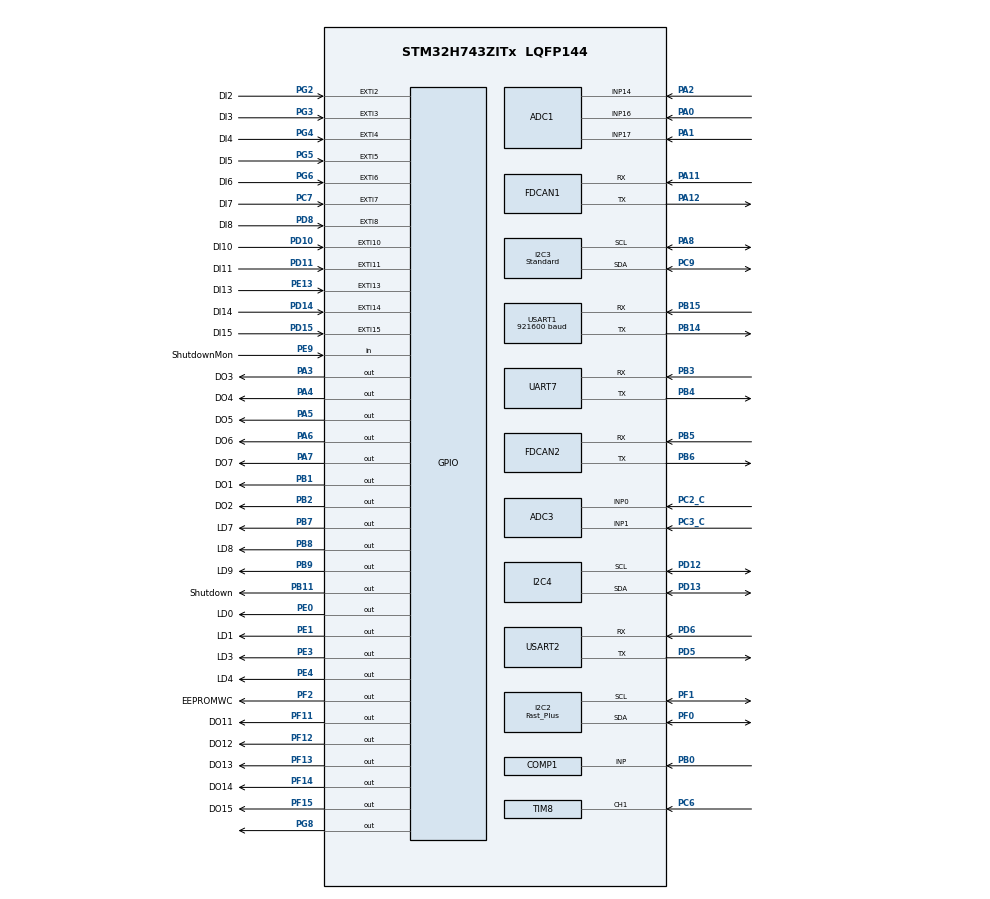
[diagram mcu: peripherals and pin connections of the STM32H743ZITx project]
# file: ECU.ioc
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ADC1.Channel-0\#ChannelRegularConversion=ADC_CHANNEL_16
ADC1.Channel-2\#ChannelRegularConversion=ADC_CHANNEL_17
ADC1.Channel-3\#ChannelRegularConversion=ADC_CHANNEL_14
ADC1.ClockPrescaler=ADC_CLOCK_ASYNC_DIV6
ADC1.ContinuousConvMode=ENABLE
ADC1.ConversionDataManagement=ADC_CONVERSIONDATA_DMA_ONESHOT
ADC1.EOCSelection=ADC_EOC_SINGLE_CONV
ADC1.NbrOfConversion=3
ADC1.NbrOfConversionFlag=1
ADC1.OffsetNumber-0\#ChannelRegularConversion=ADC_OFFSET_NONE
ADC1.OffsetNumber-2\#ChannelRegularConversion=ADC_OFFSET_NONE
ADC1.OffsetNumber-3\#ChannelRegularConversion=ADC_OFFSET_NONE
ADC1.Overrun=ADC_OVR_DATA_OVERWRITTEN
ADC1.Rank-0\#ChannelRegularConversion=1
ADC1.Rank-2\#ChannelRegularConversion=2
ADC1.Rank-3\#ChannelRegularConversion=3
ADC1.SamplingTime-0\#ChannelRegularConversion=ADC_SAMPLETIME_64CYCLES_5
ADC1.SamplingTime-2\#ChannelRegularConversion=ADC_SAMPLETIME_64CYCLES_5
ADC1.SamplingTime-3\#ChannelRegularConversion=ADC_SAMPLETIME_64CYCLES_5
ADC1.master=1
ADC3.Channel-1\#ChannelRegularConversion=ADC_CHANNEL_0
ADC3.Channel-2\#ChannelRegularConversion=ADC_CHANNEL_1
ADC3.Channel-3\#ChannelRegularConversion=ADC_CHANNEL_TEMPSENSOR
ADC3.ClockPrescaler=ADC_CLOCK_ASYNC_DIV6
ADC3.ContinuousConvMode=ENABLE
ADC3.ConversionDataManagement=ADC_CONVERSIONDATA_DMA_ONESHOT
ADC3.EOCSelection=ADC_EOC_SEQ_CONV
ADC3.NbrOfConversion=3
ADC3.NbrOfConversionFlag=1
ADC3.OffsetNumber-1\#ChannelRegularConversion=ADC_OFFSET_NONE
ADC3.OffsetNumber-2\#ChannelRegularConversion=ADC_OFFSET_NONE
ADC3.OffsetNumber-3\#ChannelRegularConversion=ADC_OFFSET_NONE
ADC3.Overrun=ADC_OVR_DATA_OVERWRITTEN
ADC3.Rank-1\#ChannelRegularConversion=1
ADC3.Rank-2\#ChannelRegularConversion=2
ADC3.Rank-3\#ChannelRegularConversion=3
ADC3.SamplingTime-1\#ChannelRegularConversion=ADC_SAMPLETIME_64CYCLES_5
ADC3.SamplingTime-2\#ChannelRegularConversion=ADC_SAMPLETIME_64CYCLES_5
ADC3.SamplingTime-3\#ChannelRegularConversion=ADC_SAMPLETIME_64CYCLES_5
COMP1.Hysteresis=COMP_HYSTERESIS_MEDIUM
COMP1.TriggerMode=COMP_TRIGGERMODE_IT_FALLING
CORTEX_M7.CPU_DCache=Enabled
CORTEX_M7.CPU_ICache=Enabled
Dma.ADC1.0.Direction=DMA_PERIPH_TO_MEMORY
Dma.ADC1.0.EventEnable=DISABLE
Dma.ADC1.0.FIFOMode=DMA_FIFOMODE_DISABLE
Dma.ADC1.0.Instance=DMA1_Stream0
Dma.ADC1.0.MemDataAlignment=DMA_MDATAALIGN_WORD
Dma.ADC1.0.MemInc=DMA_MINC_ENABLE
Dma.ADC1.0.Mode=DMA_CIRCULAR
Dma.ADC1.0.PeriphDataAlignment=DMA_PDATAALIGN_WORD
Dma.ADC1.0.PeriphInc=DMA_PINC_DISABLE
Dma.ADC1.0.Polarity=HAL_DMAMUX_REQ_GEN_RISING
Dma.ADC1.0.Priority=DMA_PRIORITY_LOW
Dma.ADC1.0.RequestNumber=1
Dma.ADC1.0.SignalID=NONE
Dma.ADC1.0.SyncEnable=DISABLE
Dma.ADC1.0.SyncPolarity=HAL_DMAMUX_SYNC_NO_EVENT
Dma.ADC1.0.SyncRequestNumber=1
Dma.ADC1.0.SyncSignalID=NONE
Dma.ADC3.1.Direction=DMA_PERIPH_TO_MEMORY
Dma.ADC3.1.EventEnable=DISABLE
Dma.ADC3.1.FIFOMode=DMA_FIFOMODE_DISABLE
Dma.ADC3.1.Instance=DMA1_Stream1
Dma.ADC3.1.MemDataAlignment=DMA_MDATAALIGN_WORD
Dma.ADC3.1.MemInc=DMA_MINC_ENABLE
Dma.ADC3.1.Mode=DMA_CIRCULAR
Dma.ADC3.1.PeriphDataAlignment=DMA_PDATAALIGN_WORD
Dma.ADC3.1.PeriphInc=DMA_PINC_DISABLE
Dma.ADC3.1.Polarity=HAL_DMAMUX_REQ_GEN_RISING
Dma.ADC3.1.Priority=DMA_PRIORITY_LOW
Dma.ADC3.1.RequestNumber=1
Dma.ADC3.1.SignalID=NONE
Dma.ADC3.1.SyncEnable=DISABLE
Dma.ADC3.1.SyncPolarity=HAL_DMAMUX_SYNC_NO_EVENT
Dma.ADC3.1.SyncRequestNumber=1
Dma.ADC3.1.SyncSignalID=NONE
Dma.Request0=ADC1
Dma.Request1=ADC3
Dma.Request2=USART2_TX
Dma.Request3=USART2_RX
Dma.Request4=USART1_TX
Dma.Request5=USART1_RX
Dma.USART1_RX.5.Direction=DMA_PERIPH_TO_MEMORY
Dma.USART1_RX.5.EventEnable=DISABLE
Dma.USART1_RX.5.FIFOMode=DMA_FIFOMODE_DISABLE
Dma.USART1_RX.5.Instance=DMA1_Stream3
Dma.USART1_RX.5.MemDataAlignment=DMA_MDATAALIGN_BYTE
Dma.USART1_RX.5.MemInc=DMA_MINC_ENABLE
Dma.USART1_RX.5.Mode=DMA_NORMAL
Dma.USART1_RX.5.PeriphDataAlignment=DMA_PDATAALIGN_BYTE
Dma.USART1_RX.5.PeriphInc=DMA_PINC_DISABLE
Dma.USART1_RX.5.Polarity=HAL_DMAMUX_REQ_GEN_RISING
Dma.USART1_RX.5.Priority=DMA_PRIORITY_LOW
Dma.USART1_RX.5.RequestNumber=1
Dma.USART1_RX.5.SignalID=NONE
Dma.USART1_RX.5.SyncEnable=DISABLE
Dma.USART1_RX.5.SyncPolarity=HAL_DMAMUX_SYNC_NO_EVENT
Dma.USART1_RX.5.SyncRequestNumber=1
Dma.USART1_RX.5.SyncSignalID=NONE
Dma.USART1_TX.4.Direction=DMA_MEMORY_TO_PERIPH
Dma.USART1_TX.4.EventEnable=DISABLE
Dma.USART1_TX.4.FIFOMode=DMA_FIFOMODE_DISABLE
Dma.USART1_TX.4.Instance=DMA1_Stream2
Dma.USART1_TX.4.MemDataAlignment=DMA_MDATAALIGN_BYTE
Dma.USART1_TX.4.MemInc=DMA_MINC_ENABLE
Dma.USART1_TX.4.Mode=DMA_NORMAL
Dma.USART1_TX.4.PeriphDataAlignment=DMA_PDATAALIGN_BYTE
Dma.USART1_TX.4.PeriphInc=DMA_PINC_DISABLE
Dma.USART1_TX.4.Polarity=HAL_DMAMUX_REQ_GEN_RISING
Dma.USART1_TX.4.Priority=DMA_PRIORITY_LOW
Dma.USART1_TX.4.RequestNumber=1
Dma.USART1_TX.4.SignalID=NONE
Dma.USART1_TX.4.SyncEnable=DISABLE
Dma.USART1_TX.4.SyncPolarity=HAL_DMAMUX_SYNC_NO_EVENT
Dma.USART1_TX.4.SyncRequestNumber=1
Dma.USART1_TX.4.SyncSignalID=NONE
Dma.USART2_RX.3.Direction=DMA_PERIPH_TO_MEMORY
Dma.USART2_RX.3.EventEnable=DISABLE
Dma.USART2_RX.3.FIFOMode=DMA_FIFOMODE_DISABLE
Dma.USART2_RX.3.Instance=DMA2_Stream1
Dma.USART2_RX.3.MemDataAlignment=DMA_MDATAALIGN_BYTE
Dma.USART2_RX.3.MemInc=DMA_MINC_ENABLE
Dma.USART2_RX.3.Mode=DMA_NORMAL
Dma.USART2_RX.3.PeriphDataAlignment=DMA_PDATAALIGN_BYTE
Dma.USART2_RX.3.PeriphInc=DMA_PINC_DISABLE
Dma.USART2_RX.3.Polarity=HAL_DMAMUX_REQ_GEN_RISING
Dma.USART2_RX.3.Priority=DMA_PRIORITY_LOW
Dma.USART2_RX.3.RequestNumber=1
Dma.USART2_RX.3.SignalID=NONE
Dma.USART2_RX.3.SyncEnable=DISABLE
Dma.USART2_RX.3.SyncPolarity=HAL_DMAMUX_SYNC_NO_EVENT
Dma.USART2_RX.3.SyncRequestNumber=1
Dma.USART2_RX.3.SyncSignalID=NONE
Dma.USART2_TX.2.Direction=DMA_MEMORY_TO_PERIPH
Dma.USART2_TX.2.EventEnable=DISABLE
Dma.USART2_TX.2.FIFOMode=DMA_FIFOMODE_DISABLE
Dma.USART2_TX.2.Instance=DMA2_Stream0
Dma.USART2_TX.2.MemDataAlignment=DMA_MDATAALIGN_BYTE
Dma.USART2_TX.2.MemInc=DMA_MINC_ENABLE
Dma.USART2_TX.2.Mode=DMA_NORMAL
Dma.USART2_TX.2.PeriphDataAlignment=DMA_PDATAALIGN_BYTE
Dma.USART2_TX.2.PeriphInc=DMA_PINC_DISABLE
Dma.USART2_TX.2.Polarity=HAL_DMAMUX_REQ_GEN_RISING
Dma.USART2_TX.2.Priority=DMA_PRIORITY_LOW
Dma.USART2_TX.2.RequestNumber=1
Dma.USART2_TX.2.SignalID=NONE
Dma.USART2_TX.2.SyncEnable=DISABLE
Dma.USART2_TX.2.SyncPolarity=HAL_DMAMUX_SYNC_NO_EVENT
Dma.USART2_TX.2.SyncRequestNumber=1
Dma.USART2_TX.2.SyncSignalID=NONE
FDCAN1.AutoRetransmission=ENABLE
FDCAN1.CalculateBaudRateNominal=1000000
FDCAN1.CalculateTimeQuantumNominal=62.5
FDCAN1.Mode=FDCAN_MODE_NORMAL
FDCAN1.NominalPrescaler=1
FDCAN1.NominalSyncJumpWidth=1
FDCAN1.NominalTimeSeg1=13
FDCAN1.NominalTimeSeg2=2
FDCAN1.RxFifo0ElmtsNbr=32
FDCAN1.RxFifo1ElmtsNbr=32
FDCAN1.StdFiltersNbr=128
FDCAN1.TxBuffersNbr=0
FDCAN1.TxEventsNbr=0
FDCAN1.TxFifoQueueElmtsNbr=32
FDCAN2.AutoRetransmission=ENABLE
FDCAN2.CalculateBaudRateNominal=1000000
FDCAN2.CalculateTimeQuantumNominal=62.5
FDCAN2.Mode=FDCAN_MODE_NORMAL
FDCAN2.NominalPrescaler=1
FDCAN2.NominalSyncJumpWidth=1
FDCAN2.NominalTimeSeg1=13
FDCAN2.NominalTimeSeg2=2
FDCAN2.RxFifo0ElmtsNbr=32
FDCAN2.RxFifo1ElmtsNbr=32
FDCAN2.StdFiltersNbr=128
FDCAN2.TxFifoQueueElmtsNbr=32
FREERTOS.HEAP_NUMBER=1
FREERTOS.Tasks01=defaultTask,24,128,StartDefaultTask,Default,NULL,Dynamic,NULL,NULL
FREERTOS.configCHECK_FOR_STACK_OVERFLOW=1
FREERTOS.configENABLE_FPU=1
FREERTOS.configGENERATE_RUN_TIME_STATS=1
FREERTOS.configRECORD_STACK_HIGH_ADDRESS=1
FREERTOS.configTOTAL_HEAP_SIZE=30720
FREERTOS.configUSE_IDLE_HOOK=1
FREERTOS.configUSE_STATS_FORMATTING_FUNCTIONS=1
I2C2.I2C_Speed_Mode=I2C_Fast_Plus
I2C2.Timing=0x0050174F
I2C3.I2C_Speed_Mode=I2C_Standard
I2C3.Speed=15
I2C3.Timing=0xF010F2FF
I2C4.Speed=50
I2C4.Timing=0x70303AEE
Mcu.Family=STM32H7
Mcu.Name=STM32H743ZITx
Mcu.Package=LQFP144
NVIC.ADC3_IRQn=true\:6\:0\:true\:false\:true\:false\:true\:true\:true
NVIC.COMP_IRQn=true\:6\:0\:true\:false\:true\:false\:false\:true\:true
NVIC.DMA1_Stream0_IRQn=true\:6\:0\:true\:false\:true\:false\:false\:true\:true
NVIC.DMA1_Stream1_IRQn=true\:6\:0\:true\:false\:true\:false\:false\:true\:true
NVIC.DMA1_Stream2_IRQn=true\:5\:0\:false\:false\:true\:true\:false\:true\:true
NVIC.DMA1_Stream3_IRQn=true\:5\:0\:false\:false\:true\:true\:false\:true\:true
NVIC.DMA2_Stream0_IRQn=true\:5\:0\:false\:false\:true\:true\:false\:true\:true
NVIC.DMA2_Stream1_IRQn=true\:5\:0\:false\:false\:true\:true\:false\:true\:true
NVIC.EXTI15_10_IRQn=true\:15\:0\:true\:false\:true\:false\:true\:true\:true
NVIC.EXTI2_IRQn=true\:15\:0\:true\:false\:true\:false\:true\:true\:true
NVIC.EXTI3_IRQn=true\:15\:0\:true\:false\:true\:false\:true\:true\:true
NVIC.EXTI4_IRQn=true\:15\:0\:true\:false\:true\:false\:true\:true\:true
NVIC.EXTI9_5_IRQn=true\:15\:0\:true\:false\:true\:false\:true\:true\:true
NVIC.FDCAN1_IT0_IRQn=true\:6\:0\:true\:false\:true\:false\:true\:true\:true
NVIC.FDCAN2_IT0_IRQn=true\:6\:0\:true\:false\:true\:false\:true\:true\:true
NVIC.I2C2_ER_IRQn=true\:6\:0\:true\:false\:true\:false\:true\:true\:true
NVIC.I2C2_EV_IRQn=true\:6\:0\:true\:false\:true\:false\:true\:true\:true
NVIC.I2C3_ER_IRQn=true\:6\:0\:true\:false\:true\:false\:true\:true\:true
NVIC.I2C3_EV_IRQn=true\:6\:0\:true\:false\:true\:false\:true\:true\:true
NVIC.I2C4_ER_IRQn=true\:6\:0\:true\:false\:true\:false\:true\:true\:true
NVIC.I2C4_EV_IRQn=true\:6\:0\:true\:false\:true\:false\:true\:true\:true
NVIC.PriorityGroup=NVIC_PRIORITYGROUP_4
NVIC.TIM16_IRQn=true\:6\:0\:true\:false\:true\:false\:true\:true\:true
NVIC.TIM17_IRQn=true\:0\:0\:false\:false\:true\:false\:false\:true\:true
NVIC.TIM6_DAC_IRQn=true\:6\:0\:true\:false\:true\:false\:true\:true\:true
NVIC.TIM7_IRQn=true\:6\:0\:true\:false\:true\:false\:true\:true\:true
NVIC.TIM8_CC_IRQn=true\:6\:0\:true\:false\:true\:false\:true\:true\:true
NVIC.TimeBase=TIM17_IRQn
NVIC.TimeBaseIP=TIM17
NVIC.UART7_IRQn=true\:5\:0\:false\:false\:true\:true\:true\:true\:true
NVIC.USART1_IRQn=true\:5\:0\:false\:false\:true\:true\:true\:true\:true
NVIC.USART2_IRQn=true\:5\:0\:false\:false\:true\:true\:true\:true\:true
PA0.Mode=IN16-Single-Ended
PA0.Signal=ADC1_INP16
PA1.Mode=IN17-Single-Ended
PA1.Signal=ADC1_INP17
PA11.Mode=FDCAN_Activate
PA11.Signal=FDCAN1_RX
PA12.Mode=FDCAN_Activate
PA12.Signal=FDCAN1_TX
PA2.Signal=ADCx_INP14
PA3.GPIO_Label=DO3
PA3.Signal=GPIO_Output
PA4.GPIO_Label=DO4
PA4.Signal=GPIO_Output
PA5.GPIO_Label=DO5
PA5.Signal=GPIO_Output
PA6.GPIO_Label=DO6
PA6.Signal=GPIO_Output
PA7.GPIO_Label=DO7
PA7.Signal=GPIO_Output
PA8.Mode=I2C
PA8.Signal=I2C3_SCL
PB0.Mode=INP
PB0.Signal=COMP1_INP
PB1.GPIO_Label=DO1
PB1.Signal=GPIO_Output
PB11.GPIO_Label=Shutdown
PB11.Signal=GPIO_Output
PB12.Signal=UART5_RX
PB13.Signal=UART5_TX
PB14.Mode=Asynchronous
PB14.Signal=USART1_TX
PB15.Mode=Asynchronous
PB15.Signal=USART1_RX
PB2.GPIO_Label=DO2
PB2.Signal=GPIO_Output
PB3\ (JTDO/TRACESWO).Mode=Asynchronous
PB3\ (JTDO/TRACESWO).Signal=UART7_RX
PB4\ (NJTRST).Mode=Asynchronous
PB4\ (NJTRST).Signal=UART7_TX
PB5.Mode=FDCAN_Activate
PB5.Signal=FDCAN2_RX
PB6.Mode=FDCAN_Activate
PB6.Signal=FDCAN2_TX
PB7.GPIO_Label=LD7
PB7.Signal=GPIO_Output
PB8.GPIO_Label=LD8
PB8.Signal=GPIO_Output
PB9.GPIO_Label=LD9
PB9.Signal=GPIO_Output
PC1.Signal=ADCx_INP11
PC2_C.Mode=IN0-Single-Ended
PC2_C.Signal=ADC3_INP0
PC3_C.Mode=IN1-Single-Ended
PC3_C.Signal=ADC3_INP1
PC6.Signal=S_TIM8_CH1
PC7.GPIO_Label=DI7
PC7.GPIO_PuPd=GPIO_PULLUP
PC7.Signal=GPXTI7
PC9.Mode=I2C
PC9.Signal=I2C3_SDA
PD10.GPIO_Label=DI10
PD10.GPIO_ModeDefaultEXTI=GPIO_MODE_IT_FALLING
PD10.GPIO_PuPd=GPIO_PULLUP
PD10.Signal=GPXTI10
PD11.GPIO_Label=DI11
PD11.GPIO_ModeDefaultEXTI=GPIO_MODE_IT_FALLING
PD11.GPIO_PuPd=GPIO_PULLUP
PD11.Signal=GPXTI11
PD12.Mode=I2C
PD12.Signal=I2C4_SCL
PD13.Mode=I2C
PD13.Signal=I2C4_SDA
PD14.GPIO_Label=DI14
PD14.GPIO_ModeDefaultEXTI=GPIO_MODE_IT_RISING
PD14.GPIO_PuPd=GPIO_PULLDOWN
PD14.Signal=GPXTI14
PD15.GPIO_Label=DI15
PD15.GPIO_ModeDefaultEXTI=GPIO_MODE_IT_RISING
PD15.GPIO_PuPd=GPIO_PULLDOWN
PD15.Signal=GPXTI15
PD5.Mode=Asynchronous
PD5.Signal=USART2_TX
PD6.Mode=Asynchronous
PD6.Signal=USART2_RX
PD8.GPIO_Label=DI8
PD8.GPIO_ModeDefaultEXTI=GPIO_MODE_IT_FALLING
PD8.GPIO_PuPd=GPIO_PULLUP
PD8.Signal=GPXTI8
PE0.GPIO_Label=LD0
PE0.Signal=GPIO_Output
PE1.GPIO_Label=LD1
PE1.Signal=GPIO_Output
PE13.GPIO_Label=DI13
PE13.GPIO_ModeDefaultEXTI=GPIO_MODE_IT_FALLING
PE13.GPIO_PuPd=GPIO_PULLUP
PE13.Signal=GPXTI13
PE3.GPIO_Label=LD3
PE3.Signal=GPIO_Output
PE4.GPIO_Label=LD4
PE4.Signal=GPIO_Output
PE9.GPIO_Label=ShutdownMon
PE9.Signal=GPIO_Input
PF0.Mode=I2C
PF0.Signal=I2C2_SDA
PF1.Mode=I2C
PF1.Signal=I2C2_SCL
PF11.GPIO_Label=DO11
PF11.Signal=GPIO_Output
PF12.GPIO_Label=DO12
PF12.Signal=GPIO_Output
PF13.GPIO_Label=DO13
PF13.Signal=GPIO_Output
PF14.GPIO_Label=DO14
PF14.Signal=GPIO_Output
PF15.GPIO_Label=DO15
PF15.Signal=GPIO_Output
PF2.GPIO_Label=EEPROMWC
PF2.Signal=GPIO_Output
PG2.GPIO_Label=DI2
PG2.GPIO_ModeDefaultEXTI=GPIO_MODE_IT_FALLING
PG2.GPIO_PuPd=GPIO_PULLUP
PG2.Signal=GPXTI2
PG3.GPIO_Label=DI3
PG3.GPIO_ModeDefaultEXTI=GPIO_MODE_IT_FALLING
PG3.GPIO_PuPd=GPIO_PULLUP
PG3.Signal=GPXTI3
PG4.GPIO_Label=DI4
PG4.GPIO_ModeDefaultEXTI=GPIO_MODE_IT_FALLING
PG4.GPIO_PuPd=GPIO_PULLUP
PG4.Signal=GPXTI4
PG5.GPIO_Label=DI5
PG5.GPIO_ModeDefaultEXTI=GPIO_MODE_IT_FALLING
PG5.GPIO_PuPd=GPIO_PULLUP
PG5.Signal=GPXTI5
PG6.GPIO_Label=DI6
PG6.GPIO_ModeDefaultEXTI=GPIO_MODE_IT_FALLING
PG6.GPIO_PuPd=GPIO_PULLUP
PG6.Signal=GPXTI6
PG8.Signal=GPIO_Output
PH0-OSC_IN\ (PH0).Mode=HSE-External-Clock-Source
PH0-OSC_IN\ (PH0).Signal=RCC_OSC_IN
PH1-OSC_OUT\ (PH1).Signal=RCC_OSC_OUT
ProjectManager.HeapSize=0x200
ProjectManager.StackSize=0x400
ProjectManager.TargetToolchain=STM32CubeIDE
RCC.ADCFreq_Value=75000000
RCC.APB1Freq_Value=120000000
RCC.APB2Freq_Value=120000000
RCC.APB3Freq_Value=120000000
RCC.APB4Freq_Value=120000000
RCC.CKPERSourceSelection=RCC_CLKPSOURCE_HSE
RCC.CortexFreq_Value=480000000
RCC.D1PPRE=RCC_APB3_DIV2
RCC.D2PPRE1=RCC_APB1_DIV2
RCC.D2PPRE2=RCC_APB2_DIV2
RCC.D3PPRE=RCC_APB4_DIV2
RCC.DIVM1=1
RCC.DIVM2=1
RCC.DIVN1=60
RCC.DIVN2=9
RCC.FDCANCLockSelection=RCC_FDCANCLKSOURCE_HSE
RCC.HCLKFreq_Value=240000000
RCC.HPRE=RCC_HCLK_DIV2
RCC.HSE_VALUE=16000000
RCC.PLL2FRACN=3072
RCC.PLL3FRACN=0
RCC.PLLFRACN=0
RCC.PLLSourceVirtual=RCC_PLLSOURCE_HSE
RCC.SPI123CLockSelection=RCC_SPI123CLKSOURCE_PLL2
RCC.SYSCLKFreq_VALUE=480000000
RCC.SYSCLKSource=RCC_SYSCLKSOURCE_PLLCLK
RCC.Spi45ClockSelection=RCC_SPI45CLKSOURCE_HSI
RCC.USBFreq_Value=480000000
SH.ADCx_INP11.0=ADC2_INP11
SH.ADCx_INP14.0=ADC1_INP14,IN14-Single-Ended
SH.S_TIM8_CH1.0=TIM8_CH1,PWM_Input_1
TIM16.Period=749
TIM16.Prescaler=19999
TIM3.Period=1249
TIM3.Prescaler=20000
TIM6.Period=149
TIM6.Prescaler=20000
TIM7.Period=149
TIM7.Prescaler=20000
TIM8.ICPolarity_1=TIM_INPUTCHANNELPOLARITY_FALLING
TIM8.Prescaler=4
USART1.BaudRate=921600
USART1.VirtualMode-Asynchronous=VM_ASYNC
USART2.FIFOMode=FIFOMODE_ENABLE
USART2.VirtualMode-Asynchronous=VM_ASYNC
VP_ADC3_TempSens_Input.Mode=IN-TempSens
VP_COMP1_VS_VREFINT34.Mode=VREFINT_34
VP_FREERTOS_VS_CMSIS_V2.Mode=CMSIS_V2
VP_RNG_VS_RNG.Mode=RNG_Activate
VP_SYS_VS_tim17.Mode=TIM17
VP_TIM16_VS_ClockSourceINT.Mode=Enable_Timer
VP_TIM16_VS_OPM.Mode=OPM_bit
VP_TIM3_VS_ClockSourceINT.Mode=Internal
VP_TIM6_VS_ClockSourceINT.Mode=Enable_Timer
VP_TIM7_VS_ClockSourceINT.Mode=Enable_Timer
VP_TIM7_VS_OPM.Mode=OPM_bit
VP_WWDG1_VS_WWDG.Mode=WWDG_Activate
board=custom

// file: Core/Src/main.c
/* USER CODE BEGIN Header */
/**
  ******************************************************************************
  * @file           : main.c
  * @brief          : Main program body
  ******************************************************************************
  * @attention
  *
  * <h2><center>&copy; Copyright (c) 2019 STMicroelectronics.
  * All rights reserved.</center></h2>
  *
  * This software component is licensed by ST under BSD 3-Clause license,
  * the "License"; You may not use this file except in compliance with the
  * License. You may obtain a copy of the License at:
  *                        opensource.org/licenses/BSD-3-Clause
  *
  ******************************************************************************
  */
/* USER CODE END Header */
#include "main.h"
#include "cmsis_os.h"
#include "adc.h"
#include "comp.h"
#include "dma.h"
#include "fdcan.h"
#include "i2c.h"
#include "rng.h"
#include "tim.h"
#include "usart.h"
#include "wwdg.h"
#include "gpio.h"

/* USER CODE BEGIN Includes */

#include "ecumain.h"
#include "errors.h"
#include "output.h"
#include "timerecu.h"
//#include "../Src/RTT/SEGGER_RTT.h"
/* USER CODE END Includes */

void SystemClock_Config(void);
void PeriphCommonClock_Config(void);
void MX_FREERTOS_Init(void);

int main(void)
{

  /* USER CODE BEGIN 1 */
  // used so that main is still generated to see all the init steps CubeMX generated
  //	so that they can be integrated into our main.
  realmain();
  /* USER CODE END 1 */

  /* Enable the CPU Cache */

  /* Enable I-Cache---------------------------------------------------------*/
  SCB_EnableICache();

  /* Enable D-Cache---------------------------------------------------------*/
  SCB_EnableDCache();

  /* MCU Configuration--------------------------------------------------------*/

  /* Reset of all peripherals, Initializes the Flash interface and the Systick. */
  HAL_Init();

  /* Configure the system clock */
  SystemClock_Config();

/* Configure the peripherals common clocks */
  PeriphCommonClock_Config();

  /* Initialize all configured peripherals */
  MX_GPIO_Init();
  MX_DMA_Init();
  MX_ADC1_Init();
  MX_ADC3_Init();
  MX_COMP1_Init();
  MX_FDCAN1_Init();
  MX_FDCAN2_Init();
  MX_I2C2_Init();
  MX_I2C3_Init();
  MX_I2C4_Init();
  MX_TIM3_Init();
  MX_USART1_UART_Init();
  MX_USART2_UART_Init();
  MX_TIM16_Init();
  MX_TIM7_Init();
  MX_TIM6_Init();
  MX_TIM8_Init();
  MX_WWDG1_Init();
  MX_RNG_Init();
  MX_UART7_Init();

  /* Init scheduler */
  osKernelInitialize();

  /* Call init function for freertos objects (in cmsis_os2.c) */
  MX_FREERTOS_Init();

  /* Start scheduler */
  osKernelStart();

  /* We should never get here as control is now taken by the scheduler */

  /* Infinite loop */
  while (1)
  {

  }
}

void SystemClock_Config(void)
{
  RCC_OscInitTypeDef RCC_OscInitStruct = {0};
  RCC_ClkInitTypeDef RCC_ClkInitStruct = {0};

  /** Supply configuration update enable
  */
  HAL_PWREx_ConfigSupply(PWR_LDO_SUPPLY);

  /** Configure the main internal regulator output voltage
  */
  __HAL_PWR_VOLTAGESCALING_CONFIG(PWR_REGULATOR_VOLTAGE_SCALE1);

  while(!__HAL_PWR_GET_FLAG(PWR_FLAG_VOSRDY)) {}

  __HAL_RCC_SYSCFG_CLK_ENABLE();
  __HAL_PWR_VOLTAGESCALING_CONFIG(PWR_REGULATOR_VOLTAGE_SCALE0);

  while(!__HAL_PWR_GET_FLAG(PWR_FLAG_VOSRDY)) {}

  /** Initializes the RCC Oscillators according to the specified parameters
  * in the RCC_OscInitTypeDef structure.
  */
  RCC_OscInitStruct.OscillatorType = RCC_OSCILLATORTYPE_HSI48|RCC_OSCILLATORTYPE_HSE;
  RCC_OscInitStruct.HSEState = RCC_HSE_BYPASS;
  RCC_OscInitStruct.HSI48State = RCC_HSI48_ON;
  RCC_OscInitStruct.PLL.PLLState = RCC_PLL_ON;
  RCC_OscInitStruct.PLL.PLLSource = RCC_PLLSOURCE_HSE;
  RCC_OscInitStruct.PLL.PLLM = 1;
  RCC_OscInitStruct.PLL.PLLN = 60;
  RCC_OscInitStruct.PLL.PLLP = 2;
  RCC_OscInitStruct.PLL.PLLQ = 2;
  RCC_OscInitStruct.PLL.PLLR = 2;
  RCC_OscInitStruct.PLL.PLLRGE = RCC_PLL1VCIRANGE_3;
  RCC_OscInitStruct.PLL.PLLVCOSEL = RCC_PLL1VCOWIDE;
  RCC_OscInitStruct.PLL.PLLFRACN = 0;
  if (HAL_RCC_OscConfig(&RCC_OscInitStruct) != HAL_OK)
  {
    Error_Handler();
  }

  /** Initializes the CPU, AHB and APB buses clocks
  */
  RCC_ClkInitStruct.ClockType = RCC_CLOCKTYPE_HCLK|RCC_CLOCKTYPE_SYSCLK
                              |RCC_CLOCKTYPE_PCLK1|RCC_CLOCKTYPE_PCLK2
                              |RCC_CLOCKTYPE_D3PCLK1|RCC_CLOCKTYPE_D1PCLK1;
  RCC_ClkInitStruct.SYSCLKSource = RCC_SYSCLKSOURCE_PLLCLK;
  RCC_ClkInitStruct.SYSCLKDivider = RCC_SYSCLK_DIV1;
  RCC_ClkInitStruct.AHBCLKDivider = RCC_HCLK_DIV2;
  RCC_ClkInitStruct.APB3CLKDivider = RCC_APB3_DIV2;
  RCC_ClkInitStruct.APB1CLKDivider = RCC_APB1_DIV2;
  RCC_ClkInitStruct.APB2CLKDivider = RCC_APB2_DIV2;
  RCC_ClkInitStruct.APB4CLKDivider = RCC_APB4_DIV2;

  if (HAL_RCC_ClockConfig(&RCC_ClkInitStruct, FLASH_LATENCY_4) != HAL_OK)
  {
    Error_Handler();
  }
}

void PeriphCommonClock_Config(void)
{
  RCC_PeriphCLKInitTypeDef PeriphClkInitStruct = {0};

  /** Initializes the peripherals clock
  */
  PeriphClkInitStruct.PeriphClockSelection = RCC_PERIPHCLK_ADC;
  PeriphClkInitStruct.PLL2.PLL2M = 1;
  PeriphClkInitStruct.PLL2.PLL2N = 9;
  PeriphClkInitStruct.PLL2.PLL2P = 2;
  PeriphClkInitStruct.PLL2.PLL2Q = 2;
  PeriphClkInitStruct.PLL2.PLL2R = 2;
  PeriphClkInitStruct.PLL2.PLL2RGE = RCC_PLL2VCIRANGE_3;
  PeriphClkInitStruct.PLL2.PLL2VCOSEL = RCC_PLL2VCOMEDIUM;
  PeriphClkInitStruct.PLL2.PLL2FRACN = 3072;
  PeriphClkInitStruct.AdcClockSelection = RCC_ADCCLKSOURCE_PLL2;
  if (HAL_RCCEx_PeriphCLKConfig(&PeriphClkInitStruct) != HAL_OK)
  {
    Error_Handler();
  }
}

void HAL_TIM_PeriodElapsedCallback(TIM_HandleTypeDef *htim)
{
  if (htim->Instance == TIM17) {
    HAL_IncTick();
  }
  /* USER CODE BEGIN Callback 1 */
  else TIM_PeriodElapsedCallback(htim);

  /* USER CODE END Callback 1 */
}

void Error_Handler(void)
{
  /* USER CODE BEGIN Error_Handler_Debug */
  /* User can add his own implementation to report the HAL error return state */

	ErrorCode = 1;

	blinkOutput(RTDMLED,LEDBLINK_FOUR, 255);
	blinkOutput(TSLED,LEDBLINK_FOUR, 255);

	// set all LED's blinking
	blinkOutput(BSPDLED,LEDBLINK_FOUR, 255);

	setOutputNOW(LED1,On);
	setOutputNOW(LED2,On);
	setOutputNOW(LED3,On);

	while ( 1 )
	{

	}
  /* USER CODE END Error_Handler_Debug */
}

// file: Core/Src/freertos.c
/* USER CODE BEGIN Header */
/**
  ******************************************************************************
  * File Name          : freertos.c
  * Description        : Code for freertos applications
  ******************************************************************************
  * @attention
  *
  * <h2><center>&copy; Copyright (c) 2020 STMicroelectronics.
  * All rights reserved.</center></h2>
  *
  * This software component is licensed by ST under Ultimate Liberty license
  * SLA0044, the "License"; You may not use this file except in compliance with
  * the License. You may obtain a copy of the License at:
  *                             www.st.com/SLA0044
  *
  ******************************************************************************
  */
/* USER CODE END Header */

#include "FreeRTOS.h"
#include "task.h"
#include "main.h"
#include "cmsis_os.h"

/* Definitions for defaultTask */
osThreadId_t defaultTaskHandle;
const osThreadAttr_t defaultTask_attributes = {
  .name = "defaultTask",
  .stack_size = 128 * 4,
  .priority = (osPriority_t) osPriorityNormal,
};

void StartDefaultTask(void *argument);

void MX_FREERTOS_Init(void); /* (MISRA C 2004 rule 8.1) */

/* Hook prototypes */
void configureTimerForRunTimeStats(void);
unsigned long getRunTimeCounterValue(void);
void vApplicationIdleHook(void);
void vApplicationStackOverflowHook(xTaskHandle xTask, signed char *pcTaskName);

/* USER CODE BEGIN 1 */
/* Functions needed when configGENERATE_RUN_TIME_STATS is on */
__weak void configureTimerForRunTimeStats(void)
{

}

__weak unsigned long getRunTimeCounterValue(void)
{
return 0;
}
/* USER CODE END 1 */

/* USER CODE BEGIN 2 */
__weak void vApplicationIdleHook( void )
{
   /* vApplicationIdleHook() will only be called if configUSE_IDLE_HOOK is set
   to 1 in FreeRTOSConfig.h. It will be called on each iteration of the idle
   task. It is essential that code added to this hook function never attempts
   to block in any way (for example, call xQueueReceive() with a block time
   specified, or call vTaskDelay()). If the application makes use of the
   vTaskDelete() API function (as this demo application does) then it is also
   important that vApplicationIdleHook() is permitted to return to its calling
   function, because it is the responsibility of the idle task to clean up
   memory allocated by the kernel to any task that has since been deleted. */
}
/* USER CODE END 2 */

/* USER CODE BEGIN 4 */
__weak void vApplicationStackOverflowHook(xTaskHandle xTask, signed char *pcTaskName)
{
   /* Run time stack overflow checking is performed if
   configCHECK_FOR_STACK_OVERFLOW is defined to 1 or 2. This hook function is
   called if a stack overflow is detected. */
}
/* USER CODE END 4 */

void MX_FREERTOS_Init(void) {

  /* Create the thread(s) */
  /* creation of defaultTask */
  defaultTaskHandle = osThreadNew(StartDefaultTask, NULL, &defaultTask_attributes);

}

void StartDefaultTask(void *argument)
{
  for(;;)
  {
    osDelay(1);
  }
}
